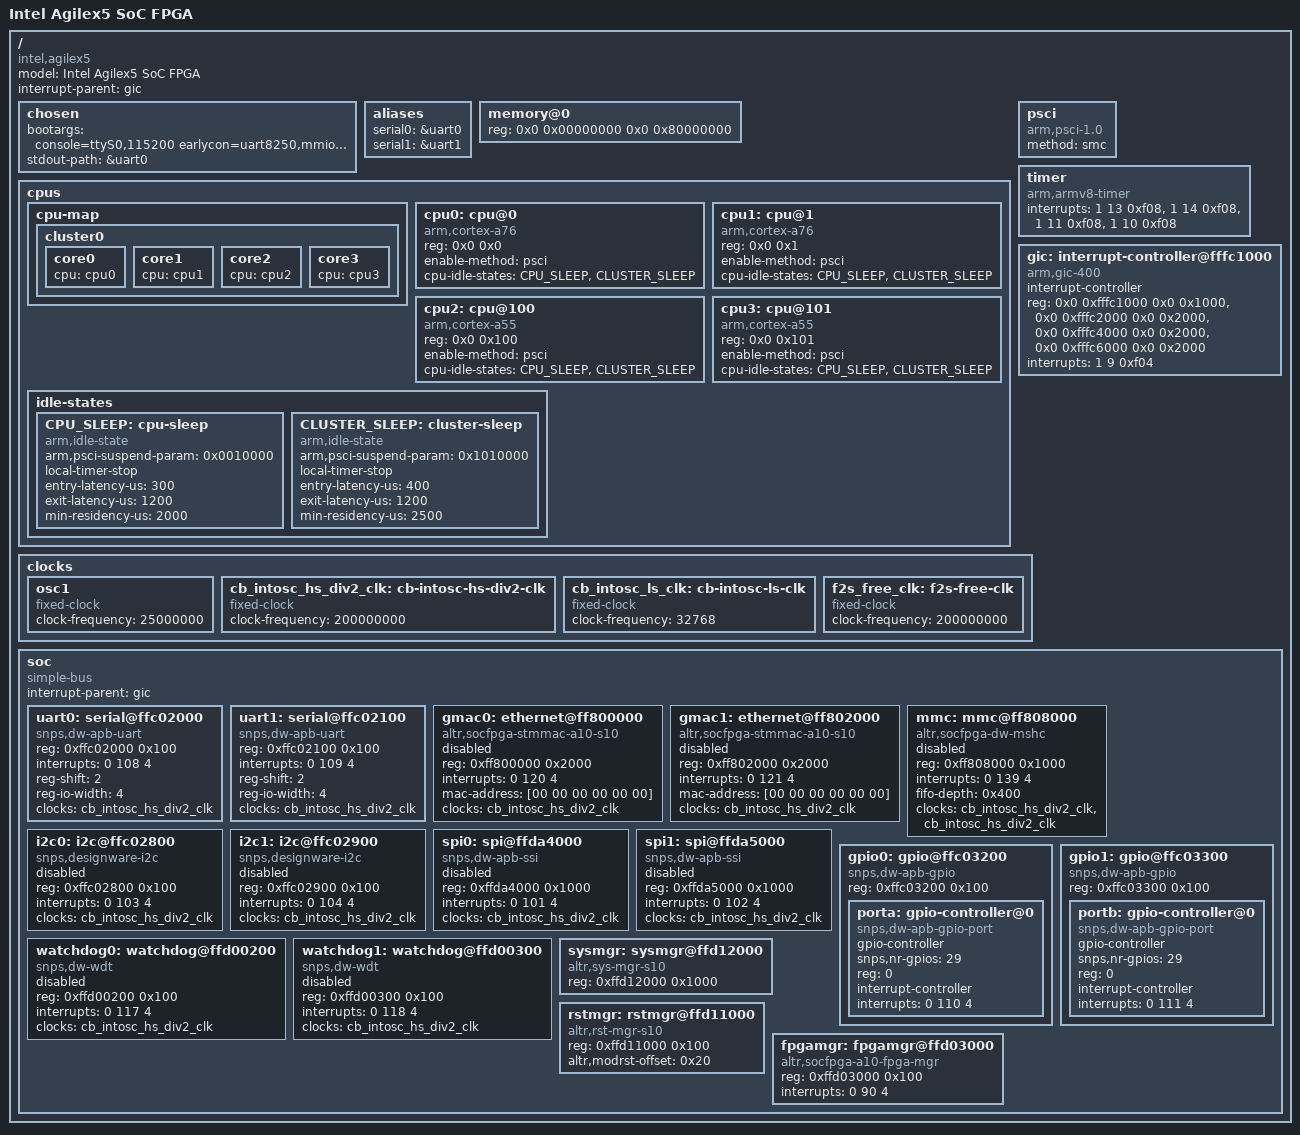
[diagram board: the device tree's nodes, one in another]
// SPDX-License-Identifier: GPL-2.0
/*
 * Device Tree for Agilex5 Hardware Platform (ARM64)
 * Intel Agilex 5 SoC FPGA with ARM Cortex-A76/A55 DynamIQ cluster
 */

/dts-v1/;

/ {
	model = "Intel Agilex5 SoC FPGA";
	compatible = "intel,agilex5";
	interrupt-parent = <&gic>;
	#address-cells = <2>;
	#size-cells = <2>;

	chosen {
		bootargs = "console=ttyS0,115200 earlycon=uart8250,mmio32,0xffc02000";
		stdout-path = &uart0;
	};

	aliases {
		serial0 = &uart0;
		serial1 = &uart1;
	};

	memory@0 {
		device_type = "memory";
		reg = <0x0 0x00000000 0x0 0x80000000>; // 2GB DRAM
	};

	cpus {
		#address-cells = <2>;
		#size-cells = <0>;

		// ARM DynamIQ cluster with Cortex-A76 (performance) and Cortex-A55 (efficiency)
		cpu-map {
			cluster0 {
				core0 {
					cpu = <&cpu0>;
				};
				core1 {
					cpu = <&cpu1>;
				};
				core2 {
					cpu = <&cpu2>;
				};
				core3 {
					cpu = <&cpu3>;
				};
			};
		};

		cpu0: cpu@0 {
			device_type = "cpu";
			compatible = "arm,cortex-a76";
			reg = <0x0 0x0>;
			enable-method = "psci";
			cpu-idle-states = <&CPU_SLEEP &CLUSTER_SLEEP>;
		};

		cpu1: cpu@1 {
			device_type = "cpu";
			compatible = "arm,cortex-a76";
			reg = <0x0 0x1>;
			enable-method = "psci";
			cpu-idle-states = <&CPU_SLEEP &CLUSTER_SLEEP>;
		};

		cpu2: cpu@100 {
			device_type = "cpu";
			compatible = "arm,cortex-a55";
			reg = <0x0 0x100>;
			enable-method = "psci";
			cpu-idle-states = <&CPU_SLEEP &CLUSTER_SLEEP>;
		};

		cpu3: cpu@101 {
			device_type = "cpu";
			compatible = "arm,cortex-a55";
			reg = <0x0 0x101>;
			enable-method = "psci";
			cpu-idle-states = <&CPU_SLEEP &CLUSTER_SLEEP>;
		};

		idle-states {
			CPU_SLEEP: cpu-sleep {
				compatible = "arm,idle-state";
				arm,psci-suspend-param = <0x0010000>;
				local-timer-stop;
				entry-latency-us = <300>;
				exit-latency-us = <1200>;
				min-residency-us = <2000>;
			};

			CLUSTER_SLEEP: cluster-sleep {
				compatible = "arm,idle-state";
				arm,psci-suspend-param = <0x1010000>;
				local-timer-stop;
				entry-latency-us = <400>;
				exit-latency-us = <1200>;
				min-residency-us = <2500>;
			};
		};
	};

	psci {
		compatible = "arm,psci-1.0", "arm,psci-0.2";
		method = "smc";
	};

	timer {
		compatible = "arm,armv8-timer";
		interrupts = <1 13 0xf08>, // Physical Secure
			     <1 14 0xf08>, // Physical Non-Secure
			     <1 11 0xf08>, // Virtual
			     <1 10 0xf08>; // Hypervisor
	};

	gic: interrupt-controller@fffc1000 {
		compatible = "arm,gic-400";
		interrupt-controller;
		#interrupt-cells = <3>;
		reg = <0x0 0xfffc1000 0x0 0x1000>,
		      <0x0 0xfffc2000 0x0 0x2000>,
		      <0x0 0xfffc4000 0x0 0x2000>,
		      <0x0 0xfffc6000 0x0 0x2000>;
		interrupts = <1 9 0xf04>;
	};

	clocks {
		osc1 {
			#clock-cells = <0>;
			compatible = "fixed-clock";
			clock-frequency = <25000000>;
		};

		cb_intosc_hs_div2_clk: cb-intosc-hs-div2-clk {
			#clock-cells = <0>;
			compatible = "fixed-clock";
			clock-frequency = <200000000>;
		};

		cb_intosc_ls_clk: cb-intosc-ls-clk {
			#clock-cells = <0>;
			compatible = "fixed-clock";
			clock-frequency = <32768>;
		};

		f2s_free_clk: f2s-free-clk {
			#clock-cells = <0>;
			compatible = "fixed-clock";
			clock-frequency = <200000000>;
		};
	};

	soc {
		#address-cells = <1>;
		#size-cells = <1>;
		compatible = "simple-bus";
		device_type = "soc";
		interrupt-parent = <&gic>;
		ranges = <0 0 0 0xffffffff>;

		uart0: serial@ffc02000 {
			compatible = "snps,dw-apb-uart";
			reg = <0xffc02000 0x100>;
			interrupts = <0 108 4>;
			reg-shift = <2>;
			reg-io-width = <4>;
			clocks = <&cb_intosc_hs_div2_clk>;
			clock-names = "baudclk";
		};

		uart1: serial@ffc02100 {
			compatible = "snps,dw-apb-uart";
			reg = <0xffc02100 0x100>;
			interrupts = <0 109 4>;
			reg-shift = <2>;
			reg-io-width = <4>;
			clocks = <&cb_intosc_hs_div2_clk>;
			clock-names = "baudclk";
		};

		gmac0: ethernet@ff800000 {
			compatible = "altr,socfpga-stmmac-a10-s10", "snps,dwmac-3.72a", "snps,dwmac";
			reg = <0xff800000 0x2000>;
			interrupts = <0 120 4>;
			interrupt-names = "macirq";
			mac-address = [00 00 00 00 00 00];
			clocks = <&cb_intosc_hs_div2_clk>;
			clock-names = "stmmaceth";
			status = "disabled";
		};

		gmac1: ethernet@ff802000 {
			compatible = "altr,socfpga-stmmac-a10-s10", "snps,dwmac-3.72a", "snps,dwmac";
			reg = <0xff802000 0x2000>;
			interrupts = <0 121 4>;
			interrupt-names = "macirq";
			mac-address = [00 00 00 00 00 00];
			clocks = <&cb_intosc_hs_div2_clk>;
			clock-names = "stmmaceth";
			status = "disabled";
		};

		mmc: mmc@ff808000 {
			compatible = "altr,socfpga-dw-mshc";
			reg = <0xff808000 0x1000>;
			interrupts = <0 139 4>;
			fifo-depth = <0x400>;
			#address-cells = <1>;
			#size-cells = <0>;
			clocks = <&cb_intosc_hs_div2_clk>, <&cb_intosc_hs_div2_clk>;
			clock-names = "biu", "ciu";
			status = "disabled";
		};

		i2c0: i2c@ffc02800 {
			compatible = "snps,designware-i2c";
			reg = <0xffc02800 0x100>;
			interrupts = <0 103 4>;
			clocks = <&cb_intosc_hs_div2_clk>;
			status = "disabled";
		};

		i2c1: i2c@ffc02900 {
			compatible = "snps,designware-i2c";
			reg = <0xffc02900 0x100>;
			interrupts = <0 104 4>;
			clocks = <&cb_intosc_hs_div2_clk>;
			status = "disabled";
		};

		spi0: spi@ffda4000 {
			compatible = "snps,dw-apb-ssi";
			reg = <0xffda4000 0x1000>;
			interrupts = <0 101 4>;
			#address-cells = <1>;
			#size-cells = <0>;
			clocks = <&cb_intosc_hs_div2_clk>;
			status = "disabled";
		};

		spi1: spi@ffda5000 {
			compatible = "snps,dw-apb-ssi";
			reg = <0xffda5000 0x1000>;
			interrupts = <0 102 4>;
			#address-cells = <1>;
			#size-cells = <0>;
			clocks = <&cb_intosc_hs_div2_clk>;
			status = "disabled";
		};

		gpio0: gpio@ffc03200 {
			compatible = "snps,dw-apb-gpio";
			reg = <0xffc03200 0x100>;
			#address-cells = <1>;
			#size-cells = <0>;

			porta: gpio-controller@0 {
				compatible = "snps,dw-apb-gpio-port";
				gpio-controller;
				#gpio-cells = <2>;
				snps,nr-gpios = <29>;
				reg = <0>;
				interrupt-controller;
				#interrupt-cells = <2>;
				interrupts = <0 110 4>;
			};
		};

		gpio1: gpio@ffc03300 {
			compatible = "snps,dw-apb-gpio";
			reg = <0xffc03300 0x100>;
			#address-cells = <1>;
			#size-cells = <0>;

			portb: gpio-controller@0 {
				compatible = "snps,dw-apb-gpio-port";
				gpio-controller;
				#gpio-cells = <2>;
				snps,nr-gpios = <29>;
				reg = <0>;
				interrupt-controller;
				#interrupt-cells = <2>;
				interrupts = <0 111 4>;
			};
		};

		watchdog0: watchdog@ffd00200 {
			compatible = "snps,dw-wdt";
			reg = <0xffd00200 0x100>;
			interrupts = <0 117 4>;
			clocks = <&cb_intosc_hs_div2_clk>;
			status = "disabled";
		};

		watchdog1: watchdog@ffd00300 {
			compatible = "snps,dw-wdt";
			reg = <0xffd00300 0x100>;
			interrupts = <0 118 4>;
			clocks = <&cb_intosc_hs_div2_clk>;
			status = "disabled";
		};

		sysmgr: sysmgr@ffd12000 {
			compatible = "altr,sys-mgr-s10","altr,sys-mgr";
			reg = <0xffd12000 0x1000>;
		};

		rstmgr: rstmgr@ffd11000 {
			compatible = "altr,rst-mgr-s10","altr,rst-mgr";
			reg = <0xffd11000 0x100>;
			altr,modrst-offset = <0x20>;
		};

		fpgamgr: fpgamgr@ffd03000 {
			compatible = "altr,socfpga-a10-fpga-mgr";
			reg = <0xffd03000 0x100>;
			interrupts = <0 90 4>;
		};
	};
};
